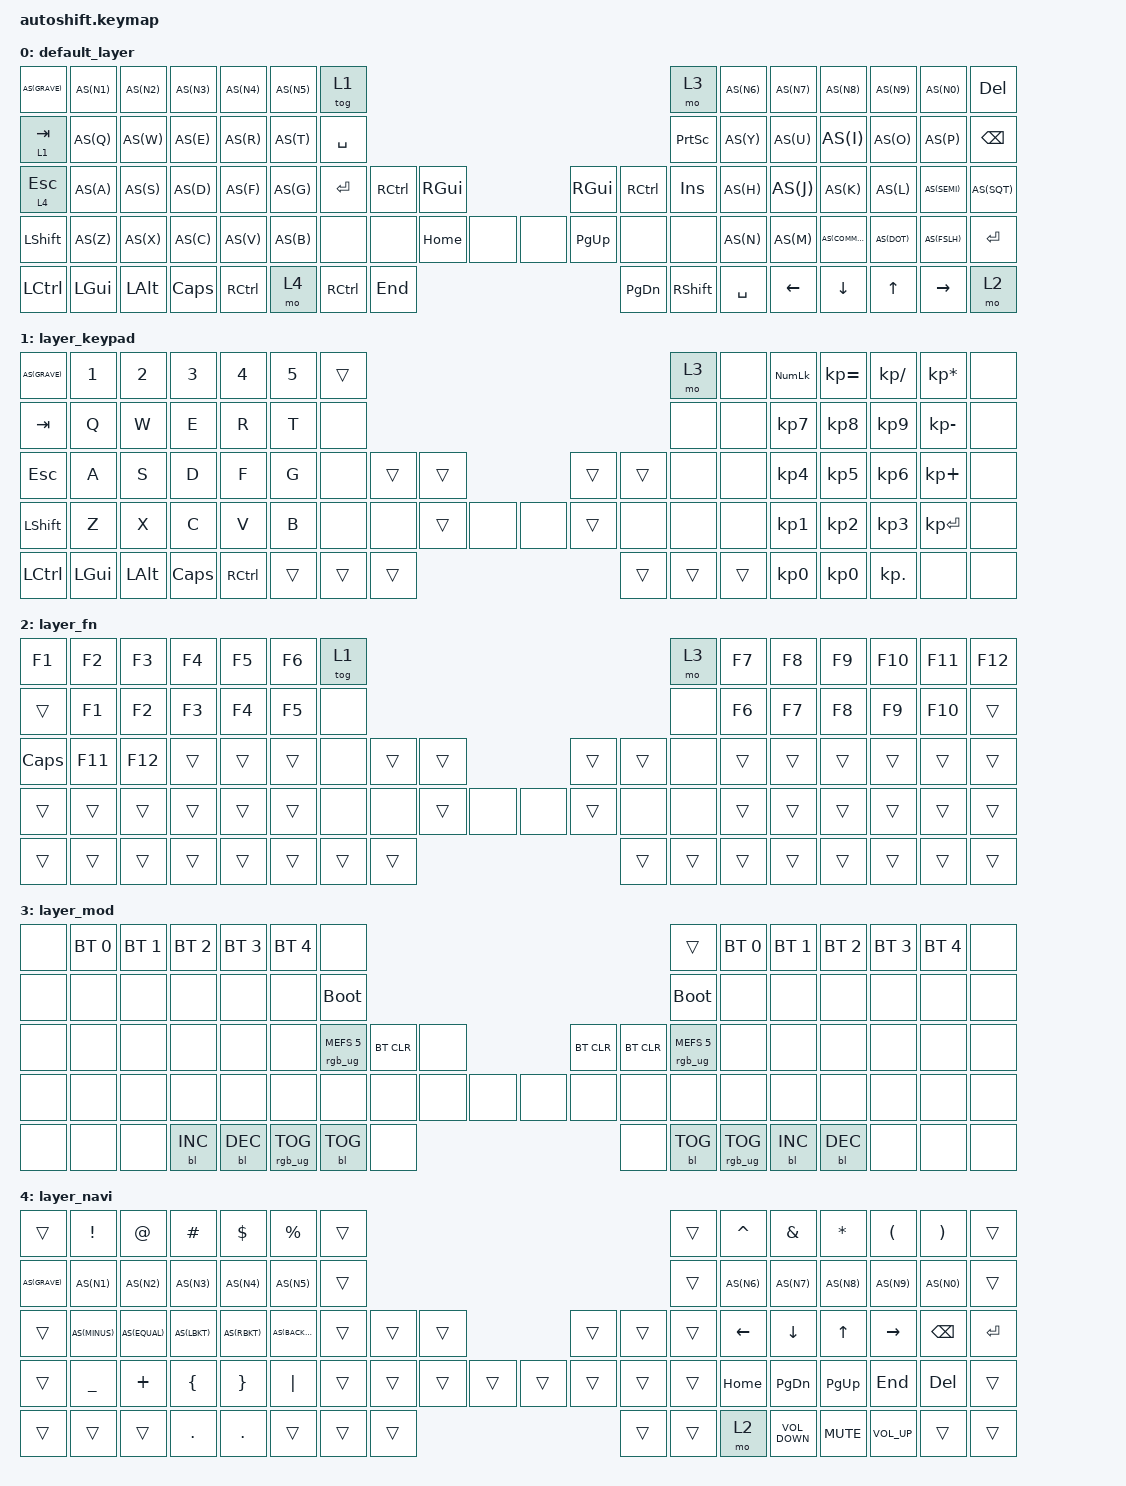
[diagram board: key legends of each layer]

/*
 * Copyright (c) 2020 The ZMK Contributors
 *
 * SPDX-License-Identifier: MIT
 */


/* THIS FILE WAS GENERATED!
 *
 * This file was generated automatically. You may or may not want to
 * edit it directly.
 */

#include <behaviors.dtsi>
#include <dt-bindings/zmk/keys.h>
#include <dt-bindings/zmk/bt.h>
#include <dt-bindings/zmk/rgb.h>
#include <dt-bindings/zmk/backlight.h>

#define AS(keycode) &as LS(keycode) keycode

/ {
        behaviors {
            as: auto_shift {
                compatible = "zmk,behavior-hold-tap";
                label = "AUTO_SHIFT";
                #binding-cells = <2>;
                tapping_term_ms = <175>;
                quick_tap_ms = <0>;
                flavor = "tap-preferred";
                bindings = <&kp>, <&kp>;
            };
        };

    keymap {
        compatible = "zmk,keymap";


        default_layer {
            bindings = <
 AS(GRAVE)      AS(N1)         AS(N2)     AS(N3)      AS(N4)   AS(N5)            &tog 1                                                                      &mo 3   AS(N6)     AS(N7)      AS(N8)     AS(N9)     AS(N0)     &kp DELETE
 &lt 1 TAB       AS(Q)          AS(W)      AS(E)       AS(R)    AS(T)         &kp SPACE                                                            &kp PRINTSCREEN    AS(Y)      AS(U)       AS(I)      AS(O)      AS(P)  &kp BACKSPACE
 &lt 4 ESC       AS(A)          AS(S)      AS(D)       AS(F)    AS(G)         &kp ENTER  &kp RCTRL  &kp RGUI                   &kp RGUI   &kp RCTRL     &kp INSERT    AS(H)      AS(J)       AS(K)      AS(L)   AS(SEMI)        AS(SQT)
 &kp LSHFT       AS(Z)          AS(X)      AS(C)       AS(V)    AS(B)             &none      &none  &kp HOME   &none   &none  &kp PG_UP       &none          &none    AS(N)      AS(M)   AS(COMMA)    AS(DOT)   AS(FSLH)      &kp ENTER
 &kp LCTRL    &kp LGUI   &kp LEFT_ALT   &kp CAPS   &kp RCTRL                 &mo 4  &kp  RCTRL   &kp END                      &kp PG_DN  &kp RSHIFT      &kp SPACE           &kp LEFT   &kp DOWN      &kp UP   &kp RIGHT          &mo 2
            >;
        };

        layer_keypad {
            bindings = <
 AS(GRAVE)     &kp N1        &kp N2    &kp N3     &kp N4  &kp N5            &trans                                                   &mo 3   &none       &kp KP_NUM     &kp KP_EQUAL  &kp KP_DIVIDE  &kp KP_MULTIPLY   &none
   &kp TAB      &kp Q         &kp W     &kp E      &kp R   &kp T             &none                                                   &none   &none        &kp KP_N7        &kp KP_N8      &kp KP_N9     &kp KP_MINUS   &none
   &kp ESC      &kp A         &kp S     &kp D      &kp F   &kp G             &none  &trans  &trans                  &trans  &trans   &none   &none        &kp KP_N4        &kp KP_N5      &kp KP_N6      &kp KP_PLUS   &none
 &kp LSHFT      &kp Z         &kp X     &kp C      &kp V   &kp B             &none   &none  &trans   &none   &none  &trans   &none   &none   &none        &kp KP_N1        &kp KP_N2      &kp KP_N3     &kp KP_ENTER   &none
 &kp LCTRL   &kp LGUI  &kp LEFT_ALT  &kp CAPS  &kp RCTRL                    &trans  &trans  &trans                  &trans  &trans  &trans                &kp KP_N0        &kp KP_N0     &kp KP_DOT            &none   &none
            >;
        };

        layer_fn {
            bindings = <
   &kp F1  &kp F2  &kp F3  &kp F4  &kp F5   &kp F6            &tog 1                                                   &mo 3   &kp F7   &kp F8  &kp F9  &kp F10  &kp F11  &kp F12
   &trans  &kp F1  &kp F2  &kp F3  &kp F4   &kp F5             &none                                                   &none   &kp F6   &kp F7  &kp F8  &kp F9   &kp F10   &trans
 &kp CAPS  &kp F11  &kp F12  &trans  &trans   &trans             &none  &trans  &trans                  &trans  &trans   &none   &trans   &trans  &trans   &trans   &trans   &trans
   &trans  &trans  &trans  &trans  &trans   &trans             &none   &none  &trans   &none   &none  &trans   &none   &none   &trans   &trans  &trans   &trans   &trans   &trans
   &trans  &trans  &trans  &trans  &trans                     &trans  &trans  &trans                  &trans  &trans  &trans            &trans  &trans   &trans   &trans   &trans
            >;
        };

        layer_mod {
            bindings = <
  &none  &bt BT_SEL 0  &bt BT_SEL 1  &bt BT_SEL 2  &bt BT_SEL 3  &bt BT_SEL 4                             &none                                                                              &trans  &bt BT_SEL 0  &bt BT_SEL 1  &bt BT_SEL 2  &bt BT_SEL 3  &bt BT_SEL 4   &none
  &none         &none         &none         &none         &none         &none                       &bootloader                                                                         &bootloader         &none         &none         &none         &none         &none   &none
  &none         &none         &none         &none         &none         &none            &rgb_ug RGB_MEFS_CMD 5  &bt BT_CLR   &none                  &bt BT_CLR  &bt BT_CLR  &rgb_ug RGB_MEFS_CMD 5         &none         &none         &none         &none         &none   &none
  &none         &none         &none         &none         &none         &none                             &none       &none   &none   &none   &none       &none       &none                   &none         &none         &none         &none         &none         &none   &none
  &none         &none         &none    &bl BL_INC    &bl BL_DEC                                 &rgb_ug RGB_TOG  &bl BL_TOG   &none                       &none  &bl BL_TOG         &rgb_ug RGB_TOG                  &bl BL_INC    &bl BL_DEC         &none         &none   &none
            >;
        };

        layer_navi {
            bindings = <
    &trans   &kp EXCL      &kp AT    &kp HASH    &kp DOLLAR      &kp PERCENT      &trans                                                  &trans       &kp CARET            &kp AMPS            &kp ASTRK            &kp LPAR          &kp RPAR         &trans
 AS(GRAVE)     AS(N1)      AS(N2)      AS(N3)        AS(N4)           AS(N5)      &trans                                                  &trans          AS(N6)              AS(N7)               AS(N8)              AS(N9)            AS(N0)         &trans
    &trans  AS(MINUS)   AS(EQUAL)    AS(LBKT)      AS(RBKT)    AS(BACKSLASH)      &trans  &trans  &trans                  &trans  &trans  &trans        &kp LEFT            &kp DOWN               &kp UP           &kp RIGHT     &kp BACKSPACE      &kp ENTER
    &trans  &kp UNDER    &kp PLUS    &kp LBRC      &kp RBRC         &kp PIPE      &trans  &trans  &trans  &trans  &trans  &trans  &trans  &trans        &kp HOME           &kp PG_DN            &kp PG_UP             &kp END        &kp DELETE         &trans
    &trans     &trans      &trans     &kp DOT       &kp DOT                       &trans  &trans  &trans                  &trans  &trans   &mo 2                   &kp C_VOLUME_DOWN           &kp C_MUTE     &kp C_VOLUME_UP            &trans         &trans           
            >;
        };

    };
};
